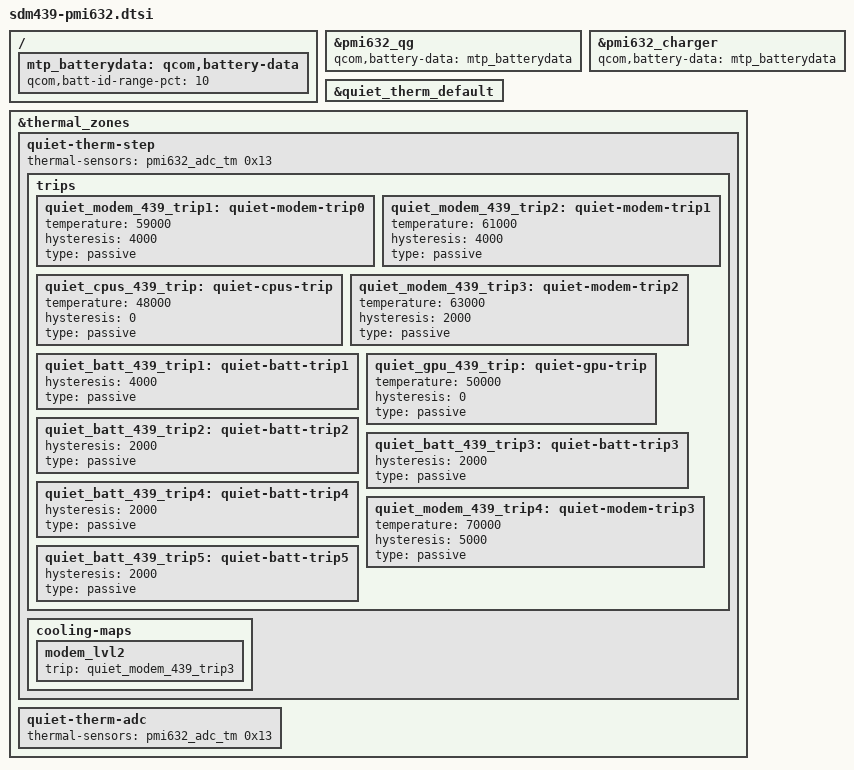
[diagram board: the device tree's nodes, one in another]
/ {
	mtp_batterydata: qcom,battery-data {
		qcom,batt-id-range-pct = <10>;
		/delete-node/ qcom,ascent_3450mah;
		/delete-node/ qcom,mlp356477_2800mah;
	};
};

&pmi632_qg {
	qcom,battery-data = <&mtp_batterydata>;
};

&pmi632_charger {
	qcom,battery-data = <&mtp_batterydata>;
};

&quiet_therm_default {
	/delete-property/ bias-disable;
};

&thermal_zones {
	quiet-therm-step {
		thermal-sensors = <&pmi632_adc_tm 0x13>;
		/delete-property/ wake-capable-sensor;
		trips {
			/delete-node/ quiet-batt-trip7;
			/delete-node/ quiet-bt-trp6-mdm-trp3;
			quiet_modem_439_trip1: quiet-modem-trip0 {
				temperature = <59000>;
				hysteresis = <4000>;
				type = "passive";
			};
			quiet_modem_439_trip2: quiet-modem-trip1 {
				temperature = <61000>;
				hysteresis = <4000>;
				type = "passive";
			};
			quiet_cpus_439_trip: quiet-cpus-trip {
				temperature = <48000>;
				hysteresis = <0>;
				type = "passive";
			};
			quiet_modem_439_trip3: quiet-modem-trip2 {
				temperature = <63000>;
				hysteresis = <2000>;
				type = "passive";
			};
			quiet_batt_439_trip1: quiet-batt-trip1 {
				hysteresis = <4000>;
				type = "passive";
			};
			quiet_gpu_439_trip: quiet-gpu-trip {
				temperature = <50000>;
				hysteresis = <0>;
				type = "passive";
			};
			quiet_batt_439_trip2: quiet-batt-trip2 {
				hysteresis = <2000>;
				type = "passive";
			};
			quiet_batt_439_trip3: quiet-batt-trip3 {
				hysteresis = <2000>;
				type = "passive";
			};
			quiet_batt_439_trip4: quiet-batt-trip4 {
				hysteresis = <2000>;
				type = "passive";
			};
			quiet_modem_439_trip4: quiet-modem-trip3 {
				temperature = <70000>;
				hysteresis = <5000>;
				type = "passive";
			};
			quiet_batt_439_trip5: quiet-batt-trip5 {
				hysteresis = <2000>;
				type = "passive";
			};
		};
		cooling-maps {
			modem_lvl2 {
				trip = <&quiet_modem_439_trip3>;
			};
			/delete-node/ battery_lvl6;
			/delete-node/ battery_lvl7;
		};
	};
	quiet-therm-adc {
		thermal-sensors = <&pmi632_adc_tm 0x13>;
		/delete-property/ wake-capable-sensor;
	};
};
